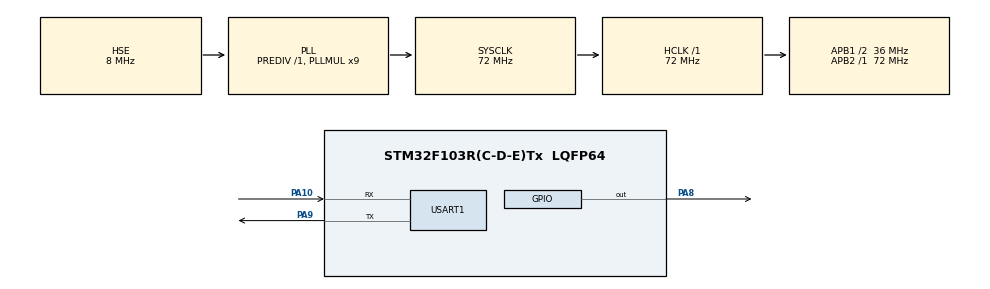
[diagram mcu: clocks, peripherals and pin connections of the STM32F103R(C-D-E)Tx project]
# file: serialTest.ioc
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Mcu.Family=STM32F1
Mcu.Name=STM32F103R(C-D-E)Tx
Mcu.Package=LQFP64
NVIC.PriorityGroup=NVIC_PRIORITYGROUP_4
PA10.Mode=Asynchronous
PA10.Signal=USART1_RX
PA13.Mode=Serial_Wire
PA13.Signal=SYS_JTMS-SWDIO
PA14.Mode=Serial_Wire
PA14.Signal=SYS_JTCK-SWCLK
PA8.Signal=GPIO_Output
PA9.Mode=Asynchronous
PA9.Signal=USART1_TX
PD0-OSC_IN.Mode=HSE-External-Oscillator
PD0-OSC_IN.Signal=RCC_OSC_IN
PD1-OSC_OUT.Mode=HSE-External-Oscillator
PD1-OSC_OUT.Signal=RCC_OSC_OUT
ProjectManager.HeapSize=0x200
ProjectManager.StackSize=0x400
ProjectManager.TargetToolchain=Makefile
RCC.AHBFreq_Value=72000000
RCC.APB1CLKDivider=RCC_HCLK_DIV2
RCC.APB1Freq_Value=36000000
RCC.APB1TimFreq_Value=72000000
RCC.APB2Freq_Value=72000000
RCC.APB2TimFreq_Value=72000000
RCC.HCLKFreq_Value=72000000
RCC.PLLMUL=RCC_PLL_MUL9
RCC.PLLSourceVirtual=RCC_PLLSOURCE_HSE
RCC.SYSCLKFreq_VALUE=72000000
RCC.SYSCLKSource=RCC_SYSCLKSOURCE_PLLCLK
RCC.USBFreq_Value=72000000
USART1.VirtualMode=VM_ASYNC
board=custom

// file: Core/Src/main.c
/* USER CODE BEGIN Header */
/**
  ******************************************************************************
  * @file           : main.c
  * @brief          : Main program body
  ******************************************************************************
  * @attention
  *
  * Copyright (c) 2024 STMicroelectronics.
  * All rights reserved.
  *
  * This software is licensed under terms that can be found in the LICENSE file
  * in the root directory of this software component.
  * If no LICENSE file comes with this software, it is provided AS-IS.
  *
  ******************************************************************************
  */
/* USER CODE END Header */
#include "main.h"
#include "usart.h"
#include "gpio.h"

/* USER CODE BEGIN PD */
#define MAX_LEN 16
/* USER CODE END PD */

/* USER CODE BEGIN PV */
uint8_t u2_RX_Buf[MAX_LEN];
uint8_t u2_RX_ReceiveBit;
int rx_len = 0;
/* USER CODE END PV */

void SystemClock_Config(void);
void Flexible_Get(void);
void Plus_two_Inputedint(void);

int main(void)
{

  /* MCU Configuration--------------------------------------------------------*/

  /* Reset of all peripherals, Initializes the Flash interface and the Systick. */
  HAL_Init();

  /* Configure the system clock */
  SystemClock_Config();

  /* Initialize all configured peripherals */
  MX_GPIO_Init();
  MX_USART1_UART_Init();

  /* Infinite loop */
  while (1)
  {
    /* USER CODE BEGIN 3 */
    Flexible_Get();
    Plus_two_Inputedint();
    HAL_GPIO_TogglePin(GPIOA, GPIO_PIN_8);
    HAL_Delay(500);
  }
  /* USER CODE END 3 */
}

void SystemClock_Config(void)
{
  RCC_OscInitTypeDef RCC_OscInitStruct = {0};
  RCC_ClkInitTypeDef RCC_ClkInitStruct = {0};

  /** Initializes the RCC Oscillators according to the specified parameters
  * in the RCC_OscInitTypeDef structure.
  */
  RCC_OscInitStruct.OscillatorType = RCC_OSCILLATORTYPE_HSE;
  RCC_OscInitStruct.HSEState = RCC_HSE_ON;
  RCC_OscInitStruct.HSEPredivValue = RCC_HSE_PREDIV_DIV1;
  RCC_OscInitStruct.HSIState = RCC_HSI_ON;
  RCC_OscInitStruct.PLL.PLLState = RCC_PLL_ON;
  RCC_OscInitStruct.PLL.PLLSource = RCC_PLLSOURCE_HSE;
  RCC_OscInitStruct.PLL.PLLMUL = RCC_PLL_MUL9;
  if (HAL_RCC_OscConfig(&RCC_OscInitStruct) != HAL_OK)
  {
    Error_Handler();
  }

  /** Initializes the CPU, AHB and APB buses clocks
  */
  RCC_ClkInitStruct.ClockType = RCC_CLOCKTYPE_HCLK|RCC_CLOCKTYPE_SYSCLK
                              |RCC_CLOCKTYPE_PCLK1|RCC_CLOCKTYPE_PCLK2;
  RCC_ClkInitStruct.SYSCLKSource = RCC_SYSCLKSOURCE_PLLCLK;
  RCC_ClkInitStruct.AHBCLKDivider = RCC_SYSCLK_DIV1;
  RCC_ClkInitStruct.APB1CLKDivider = RCC_HCLK_DIV2;
  RCC_ClkInitStruct.APB2CLKDivider = RCC_HCLK_DIV1;

  if (HAL_RCC_ClockConfig(&RCC_ClkInitStruct, FLASH_LATENCY_2) != HAL_OK)
  {
    Error_Handler();
  }
}

/**
  * @brief Flexible_Get
  * @retval None
  */
void Flexible_Get(void){
  while(1){
    while(HAL_UART_Receive(&huart1, &u2_RX_ReceiveBit, 1, 100) != HAL_OK);
    if(u2_RX_ReceiveBit == '\n'){
      if(rx_len > 0 && u2_RX_Buf[rx_len-1] == '\r'){
        u2_RX_Buf[rx_len-1] = '\0';
        rx_len = 0;
        break;
      }
      else{
        rx_len = 0;
      }
    }
    else{
      u2_RX_Buf[rx_len++] = u2_RX_ReceiveBit;
    }
  }
  if(rx_len == MAX_LEN){
    u1_printf("Input too long\r\n");
    HAL_UART_Transmit(&huart1, u2_RX_Buf, rx_len, HAL_MAX_DELAY);
    u1_printf("\r\n");
    u2_RX_Buf[MAX_LEN] = '\0';
    rx_len = 0;
  }
}

/**
  * @brief Plus_two_Inputedint
  * @retval None
  */
void Plus_two_Inputedint(void){
  uint8_t* space;
  uint8_t* end;
  int num1, num2;
  space = find_space(u2_RX_Buf);
  if(space == NULL){
    u1_printf("No space\r\n");
    return;
  }
  num1 = get_num(u2_RX_Buf, space);
  u1_printf("First: %d\r\n", num1);
  end = find_end(space);
  if(end == NULL){
    u1_printf("No end\r\n");
    return;
  }
  num2 = get_num(space+1, end);
  u1_printf("Second: %d\r\n", num2);
  u1_printf("Sum: %d\r\n", num1+num2);
}

void Error_Handler(void)
{
  __disable_irq();
  while (1)
  {
  }
}
